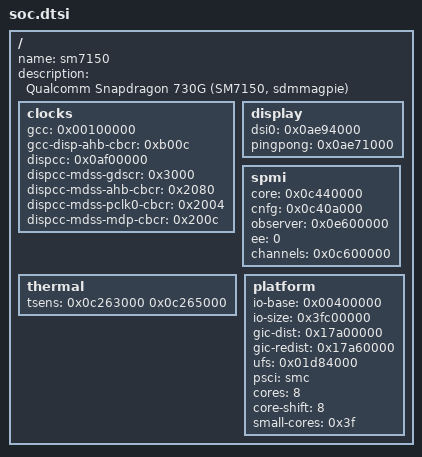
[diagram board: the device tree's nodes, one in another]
/dts-v1/;

// sm7150. Started by tools/boards.py new from phone.dts.
// What every board with this SoC shares: where its blocks are (Documentation/porting.md).
/ {
	name = "sm7150";
	description = "Qualcomm Snapdragon 730G (SM7150, sdmmagpie)";

	// The clocks the display block's registers need before they can be read: for a "dcs" backlight and
	// the feature "display-scan". The addresses are in the tree; the offsets are not -- they are in Linux's
	// clock drivers for the SoC (gcc-CODENAME.c, dispcc-CODENAME.c).
	clocks {
		gcc = <0x00100000>;             // clock-controller@100000 (qcom,CODENAME-gcc); the only key of this section
		                                // that the part drivers need
		gcc-disp-ahb-cbcr = <0xb00c>;   // gcc_disp_ahb_clk (msm-4.14 gcc-sdmmagpie.c)
		dispcc = <0x0af00000>;          // clock-controller@af00000 (qcom,CODENAME-dispcc)
		dispcc-mdss-gdscr = <0x3000>;   // mdss_core_gdsc (sdmmagpie-gdsc.dtsi: 0xaf03000)
		dispcc-mdss-ahb-cbcr = <0x2080>; // disp_cc_mdss_ahb_clk (dispcc-sdmmagpie.c)
		dispcc-mdss-pclk0-cbcr = <0x2004>; // disp_cc_mdss_pclk0_clk  } only looked at, by display_probe=1
		dispcc-mdss-mdp-cbcr = <0x200c>; // disp_cc_mdss_mdp_clk    }
	};

	display {
		dsi0 = <0x0ae94000>;            // the first DSI controller (cell-index 0), reg "dsi_ctrl"
		pingpong = <0x0ae71000>;        // PINGPONG_0: MDP 0xae01000 + 0x70000 (Linux dpu_5_2_sm7150.h; the 16.5
		                                // port's cmdpanel turned autorefresh on there, on this phone)
	};

	// (pins { }: not yet. The SM7150's TLMM is in tiles -- west 0x03500000, north 0x03900000, south 0x03d00000
	// (pinctrl-sdmmagpie.c, the 16.5 port's drivers) -- where pins { } has one base; added with the first part driver.)

	// The PMIC arbiter (qcom,spmi-pmic-arb), by its reg-names: for the features "buttons-pmic",
	// "torch-pm8350c" and "camera-sm7325".
	spmi {
		core = <0x0c440000>;            // "core"
		cnfg = <0x0c40a000>;            // "cnfg"
		observer = <0x0e600000>;        // "obsrvr": reads
		ee = <0>;                       // qcom,ee; optional, 0 if left out
		channels = <0x0c600000>;        // "chnls": writes; optional, needed only by the drivers that write to a PMIC
	};

	// Temperature, for a board's thermal { }.
	thermal {
		tsens = <0x0c263000 0x0c265000>; // the TSENS controllers (at most eight), reg "tsens_tm_physical"
	};


	// What the loader (arch/arm64/boot/) tells the kernel of the machine, for boards with a loader { } section.
	platform {
		io-base = <0x00400000>;         // one window over the SoC's peripherals, never 0 (the 16.5 loader's, run on
		io-size = <0x3fc00000>;         // this phone)
		gic-dist = <0x17a00000>;        // the arm,gic-v3 node's reg: its first entry
		gic-redist = <0x17a60000>;      // ... its second
		ufs = <0x01d84000>;             // optional: the UFS host controller (the ufshc node's reg "ufs_mem"), for the
		                                // loader's and the kernel's own requests to the storage (ufs_native=)
		psci = "smc";                   // the psci node's method: "smc" or "hvc"
		cores = <8>;                    // the cpu@ nodes
		core-shift = <8>;               // where the core's number is in its reg: 8 for 0x000, 0x100 ..., 0 for 0, 1 ...
		small-cores = <0x3f>;           // cores 0-5 Cortex-A55; 6 and 7 Cortex-A76
	};
};
